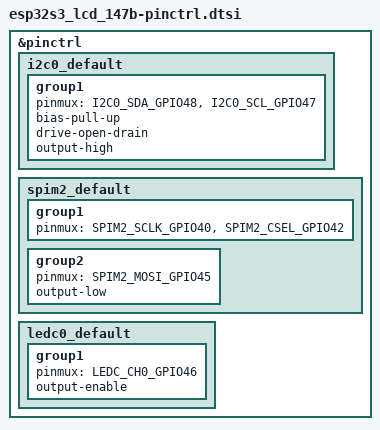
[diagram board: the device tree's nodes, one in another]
/*
 * Waveshare ESP32-S3-LCD-1.47B (rev B3) pinmux
 * TFT: MOSI=45 SCLK=40 CS=42  |  DC=41 RST=39 BL=46 (PWM)
 * IMU I2C: SDA=48 SCL=47  |  WS2812 data=38 (SPI3 MOSI bitbang)
 */

#include <dt-bindings/pinctrl/esp32s3-pinctrl.h>
#include <zephyr/dt-bindings/pinctrl/esp-pinctrl-common.h>
#include <zephyr/dt-bindings/pinctrl/esp32s3-gpio-sigmap.h>

&pinctrl {
	i2c0_default: i2c0_default {
		group1 {
			pinmux = <I2C0_SDA_GPIO48>, <I2C0_SCL_GPIO47>;
			bias-pull-up;
			drive-open-drain;
			output-high;
		};
	};

	spim2_default: spim2_default {
		group1 {
			pinmux = <SPIM2_SCLK_GPIO40>, <SPIM2_CSEL_GPIO42>;
		};
		group2 {
			pinmux = <SPIM2_MOSI_GPIO45>;
			output-low;
		};
	};

	ledc0_default: ledc0_default {
		group1 {
			pinmux = <LEDC_CH0_GPIO46>;
			output-enable;
		};
	};
};
